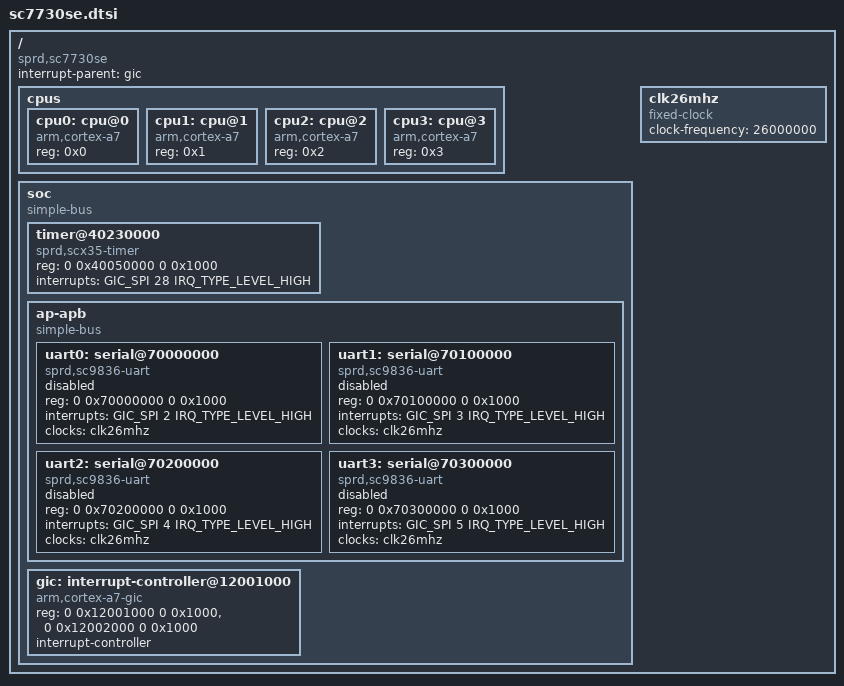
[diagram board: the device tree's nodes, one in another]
/dts-v1/;

#include <dt-bindings/interrupt-controller/irq.h>
#include <dt-bindings/interrupt-controller/arm-gic.h>

/ {
	compatible = "sprd,sc7730se";
	#address-cells = <2>;
	#size-cells = <2>;
	interrupt-parent = <&gic>;

	cpus {
		#address-cells = <1>;
		#size-cells = <0>;

		cpu0: cpu@0 {
			device_type = "cpu";
			compatible = "arm,cortex-a7";
			reg = <0x0>;
		};

		cpu1: cpu@1 {
			device_type = "cpu";
			compatible = "arm,cortex-a7";
			reg = <0x1>;
		};

		cpu2: cpu@2 {
			device_type = "cpu";
			compatible = "arm,cortex-a7";
			reg = <0x2>;
		};

		cpu3: cpu@3 {
			device_type = "cpu";
			compatible = "arm,cortex-a7";
			reg = <0x3>;
		};
	};

	soc {
		compatible = "simple-bus";
		#address-cells = <2>;
		#size-cells = <2>;
		ranges;

		timer@40230000 {
			compatible = "sprd,scx35-timer";
			reg = <0 0x40050000 0 0x1000>;
			interrupts = <GIC_SPI 28 IRQ_TYPE_LEVEL_HIGH>;
		};

		ap-apb {
			compatible = "simple-bus";
			#address-cells = <2>;
			#size-cells = <2>;
			ranges;

			uart0: serial@70000000 {
				compatible = "sprd,sc9836-uart";
				reg = <0 0x70000000 0 0x1000>;
				interrupts = <GIC_SPI 2 IRQ_TYPE_LEVEL_HIGH>;
				clocks = <&clk26mhz>;
				status = "disabled";
			};

			uart1: serial@70100000 {
				compatible = "sprd,sc9836-uart";
				reg = <0 0x70100000 0 0x1000>;
				interrupts = <GIC_SPI 3 IRQ_TYPE_LEVEL_HIGH>;
				clocks = <&clk26mhz>;
				status = "disabled";
			};

			uart2: serial@70200000 {
				compatible = "sprd,sc9836-uart";
				reg = <0 0x70200000 0 0x1000>;
				interrupts = <GIC_SPI 4 IRQ_TYPE_LEVEL_HIGH>;
				clocks = <&clk26mhz>;
				status = "disabled";
			};

			uart3: serial@70300000 {
				compatible = "sprd,sc9836-uart";
				reg = <0 0x70300000 0 0x1000>;
				interrupts = <GIC_SPI 5 IRQ_TYPE_LEVEL_HIGH>;
				clocks = <&clk26mhz>;
				status = "disabled";
			};
		};

		gic: interrupt-controller@12001000 {
			compatible = "arm,cortex-a7-gic";
			reg = <0 0x12001000 0 0x1000>,
			      <0 0x12002000 0 0x1000>;
			#interrupt-cells = <3>;
			interrupt-controller;
		};
	};

	clk26mhz: clk26mhz {
		compatible = "fixed-clock";
		#clock-cells = <0>;
		clock-frequency = <26000000>;
	};
};
